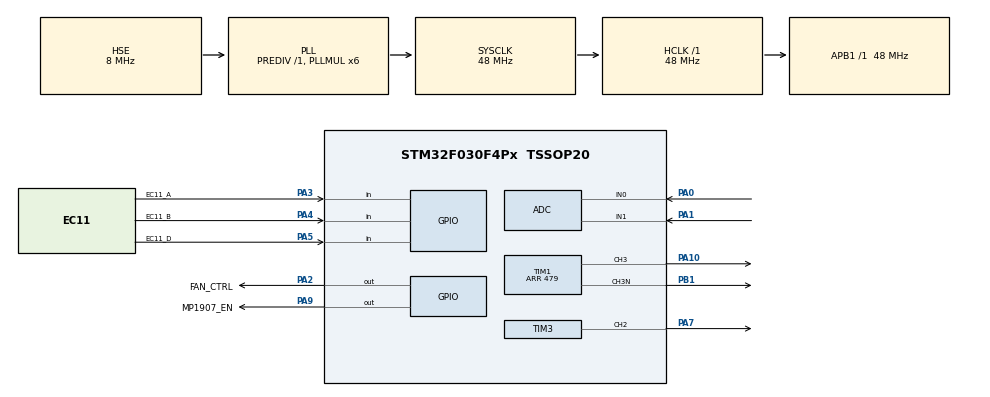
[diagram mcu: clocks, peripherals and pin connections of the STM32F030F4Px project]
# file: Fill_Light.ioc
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ADC.ContinuousConvMode=DISABLE
ADC.DMAContinuousRequests=DISABLE
ADC.EOCSelection=ADC_EOC_SEQ_CONV
ADC.SamplingTime=ADC_SAMPLETIME_239CYCLES_5
Dma.ADC.0.Direction=DMA_PERIPH_TO_MEMORY
Dma.ADC.0.Instance=DMA1_Channel1
Dma.ADC.0.MemDataAlignment=DMA_MDATAALIGN_HALFWORD
Dma.ADC.0.MemInc=DMA_MINC_ENABLE
Dma.ADC.0.Mode=DMA_NORMAL
Dma.ADC.0.PeriphDataAlignment=DMA_PDATAALIGN_HALFWORD
Dma.ADC.0.PeriphInc=DMA_PINC_DISABLE
Dma.ADC.0.Priority=DMA_PRIORITY_LOW
Dma.Request0=ADC
Mcu.Family=STM32F0
Mcu.Name=STM32F030F4Px
Mcu.Package=TSSOP20
NVIC.DMA1_Channel1_IRQn=true\:0\:0\:false\:false\:true\:false\:true\:true
NVIC.TIM14_IRQn=true\:0\:0\:false\:false\:true\:true\:true\:true
PA0.Mode=IN0
PA0.Signal=ADC_IN0
PA1.Mode=IN1
PA1.Signal=ADC_IN1
PA10.Signal=S_TIM1_CH3
PA13.Mode=Serial_Wire
PA13.Signal=SYS_SWDIO
PA14.Mode=Serial_Wire
PA14.Signal=SYS_SWCLK
PA2.GPIO_Label=FAN_CTRL
PA2.Signal=GPIO_Output
PA3.GPIO_Label=EC11_A
PA3.GPIO_PuPd=GPIO_PULLUP
PA3.Signal=GPIO_Input
PA4.GPIO_Label=EC11_B
PA4.GPIO_PuPd=GPIO_PULLUP
PA4.Signal=GPIO_Input
PA5.GPIO_Label=EC11_D
PA5.GPIO_PuPd=GPIO_PULLUP
PA5.Signal=GPIO_Input
PA7.Signal=S_TIM3_CH2
PA9.GPIO_Label=MP1907_EN
PA9.Signal=GPIO_Output
PB1.Mode=PWM Generation3 CH3 CH3N
PB1.Signal=TIM1_CH3N
PF0-OSC_IN.Mode=HSE-External-Oscillator
PF0-OSC_IN.Signal=RCC_OSC_IN
PF1-OSC_OUT.Mode=HSE-External-Oscillator
PF1-OSC_OUT.Signal=RCC_OSC_OUT
ProjectManager.HeapSize=0x200
ProjectManager.StackSize=0x400
ProjectManager.TargetToolchain=MDK-ARM V5
RCC.AHBFreq_Value=48000000
RCC.APB1Freq_Value=48000000
RCC.APB1TimFreq_Value=48000000
RCC.HCLKFreq_Value=48000000
RCC.PLLMUL=RCC_PLL_MUL6
RCC.PLLSourceVirtual=RCC_PLLSOURCE_HSE
RCC.SYSCLKFreq_VALUE=48000000
RCC.SYSCLKSource=RCC_SYSCLKSOURCE_PLLCLK
SH.S_TIM1_CH3.0=TIM1_CH3,PWM Generation3 CH3 CH3N
SH.S_TIM3_CH2.0=TIM3_CH2,PWM Generation2 CH2
TIM1.AutoReloadPreload=TIM_AUTORELOAD_PRELOAD_ENABLE
TIM1.Channel-PWM\ Generation3\ CH3\ CH3N=TIM_CHANNEL_3
TIM1.DeadTime=15
TIM1.Period=479
TIM14.AutoReloadPreload=TIM_AUTORELOAD_PRELOAD_ENABLE
TIM14.Period=499
TIM14.Prescaler=47
TIM3.Channel-PWM\ Generation2\ CH2=TIM_CHANNEL_2
TIM3.Period=999
VP_TIM14_VS_ClockSourceINT.Mode=Enable_Timer
VP_TIM1_VS_ClockSourceINT.Mode=Internal
VP_TIM3_VS_ClockSourceINT.Mode=Internal
board=custom

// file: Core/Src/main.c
/* USER CODE BEGIN Header */
/**
  ******************************************************************************
  * @file           : main.c
  * @brief          : Main program body
  ******************************************************************************
  * @attention
  *
  * Copyright (c) 2026 STMicroelectronics.
  * All rights reserved.
  *
  * This software is licensed under terms that can be found in the LICENSE file
  * in the root directory of this software component.
  * If no LICENSE file comes with this software, it is provided AS-IS.
  *
  ******************************************************************************
  */
/* USER CODE END Header */
#include "main.h"
#include "adc.h"
#include "dma.h"
#include "tim.h"
#include "gpio.h"

/* USER CODE BEGIN Includes */
#include "program.h"

/* USER CODE END Includes */

void SystemClock_Config(void);

int main(void)
{

  /* MCU Configuration--------------------------------------------------------*/

  /* Reset of all peripherals, Initializes the Flash interface and the Systick. */
  HAL_Init();

  /* Configure the system clock */
  SystemClock_Config();

  /* Initialize all configured peripherals */
  MX_GPIO_Init();
  MX_DMA_Init();
  MX_ADC_Init();
  MX_TIM1_Init();
  MX_TIM3_Init();
  MX_TIM14_Init();
  /* USER CODE BEGIN 2 */
  /* 先做ADC校准，再进入mV整定，避免后续闭环一直背着固定零点误差。 */
  if (HAL_ADCEx_Calibration_Start(&hadc) != HAL_OK)
  {
    Error_Handler();
  }
	hardware_config();
  /* USER CODE END 2 */

  /* Infinite loop */
  while (1)
  {

    /* USER CODE BEGIN 3 */
		/* 状态机放在线程上下文跑，避免ADC完成中断被业务逻辑拖长。 */
		program_task();
  }
  /* USER CODE END 3 */
}

void SystemClock_Config(void)
{
  RCC_OscInitTypeDef RCC_OscInitStruct = {0};
  RCC_ClkInitTypeDef RCC_ClkInitStruct = {0};

  /** Initializes the RCC Oscillators according to the specified parameters
  * in the RCC_OscInitTypeDef structure.
  */
  RCC_OscInitStruct.OscillatorType = RCC_OSCILLATORTYPE_HSI14|RCC_OSCILLATORTYPE_HSE;
  RCC_OscInitStruct.HSEState = RCC_HSE_ON;
  RCC_OscInitStruct.HSI14State = RCC_HSI14_ON;
  RCC_OscInitStruct.HSI14CalibrationValue = 16;
  RCC_OscInitStruct.PLL.PLLState = RCC_PLL_ON;
  RCC_OscInitStruct.PLL.PLLSource = RCC_PLLSOURCE_HSE;
  RCC_OscInitStruct.PLL.PLLMUL = RCC_PLL_MUL6;
  RCC_OscInitStruct.PLL.PREDIV = RCC_PREDIV_DIV1;
  if (HAL_RCC_OscConfig(&RCC_OscInitStruct) != HAL_OK)
  {
    Error_Handler();
  }

  /** Initializes the CPU, AHB and APB buses clocks
  */
  RCC_ClkInitStruct.ClockType = RCC_CLOCKTYPE_HCLK|RCC_CLOCKTYPE_SYSCLK
                              |RCC_CLOCKTYPE_PCLK1;
  RCC_ClkInitStruct.SYSCLKSource = RCC_SYSCLKSOURCE_PLLCLK;
  RCC_ClkInitStruct.AHBCLKDivider = RCC_SYSCLK_DIV1;
  RCC_ClkInitStruct.APB1CLKDivider = RCC_HCLK_DIV1;

  if (HAL_RCC_ClockConfig(&RCC_ClkInitStruct, FLASH_LATENCY_1) != HAL_OK)
  {
    Error_Handler();
  }
}

void Error_Handler(void)
{
  __disable_irq();
  while (1)
  {
  }
}
